# WUGEN_DSP register map
Vendor: Texas Instruments
Peripheral module from a debugger description file (folder omap5430_ES2_PUBLIC).
Registers are 32-bit, read-only, reset 0x0 unless marked. A register's access mark holds for its fields unless they carry their own. Offsets are as the file gives them; lines under a group give offsets from that group; [hi:lo] are bit positions; {n}, {i} and the like mark numbered series; 'fields as' and 'values as' point back to an identical list; <NAME> marks a mode.

## WUGEN_DSP
0x00 WUGEN_REVISION reset not defined — This register contains the IP revision code
  [31:0] REVISION — IP Revision
0x08 WUGEN_SYSCONFIG rw reset 0x1 — This register allows controlling various parameters of the WUGEN_DSP module
  [0] AUTOIDLE — Internal auto-clock gating strategy 0: Clock is free running 1: Automatic clock gating strategy is applied
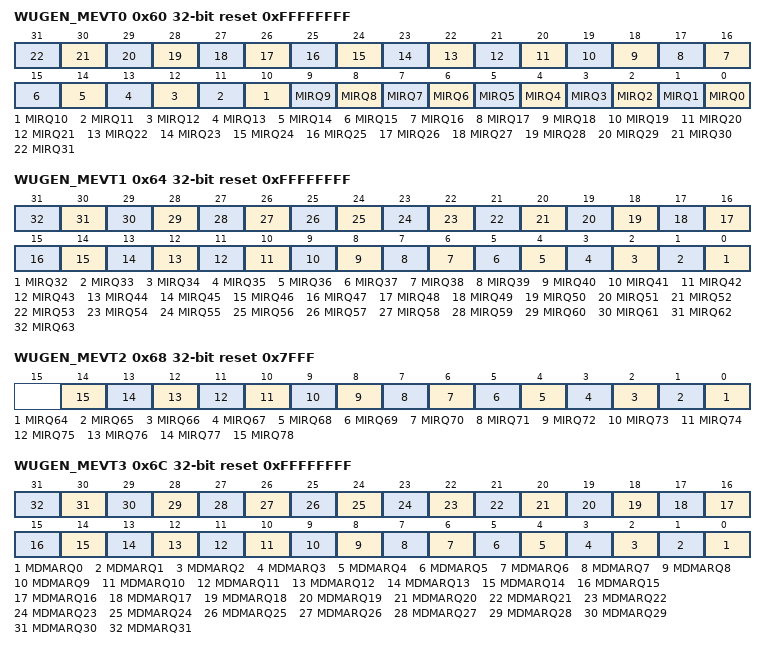
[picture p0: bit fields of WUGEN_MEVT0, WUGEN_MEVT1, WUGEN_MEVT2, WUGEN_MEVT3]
0x60 WUGEN_MEVT0 reset 0xFFFFFFFF — This register contains the interrupt mask (LSB)
  [n] MIRQ{n} (n=0..31) — Interrupt Mask bit #{n}
0x64 WUGEN_MEVT1 reset 0xFFFFFFFF — This register contains the interrupt mask (MSB)
  [n-32] MIRQ{n} (n=32..63) — Interrupt Mask bit #{n}
0x68 WUGEN_MEVT2 reset 0x7FFF — This register contains the interrupt mask (MSB)
  [n-64] MIRQ{n} (n=64..78) — Interrupt Mask bit #{n}
0x6C WUGEN_MEVT3 reset 0xFFFFFFFF — This register contains the dma request mask
  [n] MDMARQ{n} (n=0..31) — DMA request Mask bit #{n}
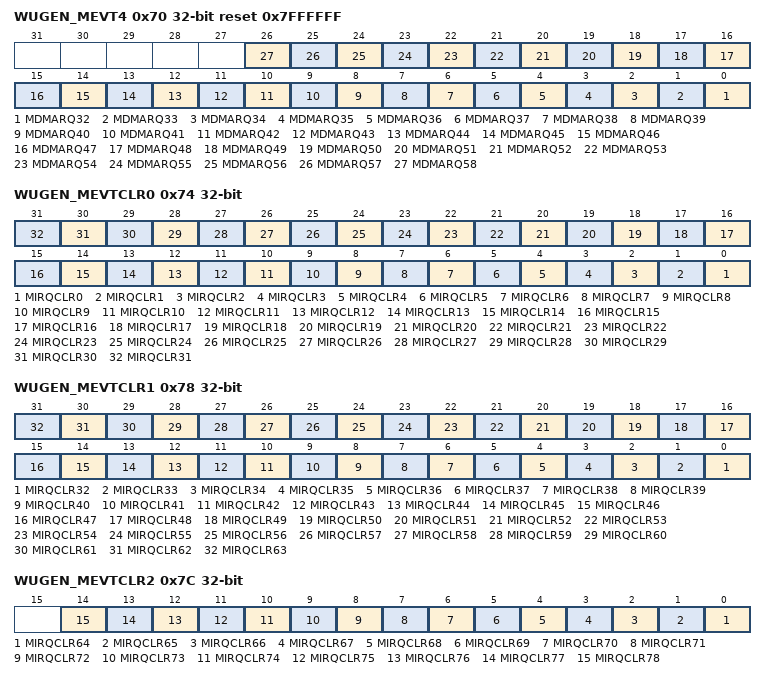
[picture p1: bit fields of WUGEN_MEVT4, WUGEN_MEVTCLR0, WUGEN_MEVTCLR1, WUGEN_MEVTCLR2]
0x70 WUGEN_MEVT4 reset 0x7FFFFFF — This register contains the dma request mask
  [n-32] MDMARQ{n} (n=32..58) — DMA request Mask bit #{n}
0x74 WUGEN_MEVTCLR0 access not given — This register is used to clear the interrupt mask bits (LSB) write 0: no effect write 1: clears the corresponding mask bit in the register reads always return 0
  [n] MIRQCLR{n} (n=0..31) — MIRQ clear #{n} (access W W1toSet)
0x78 WUGEN_MEVTCLR1 access not given — This register is used to clear the interrupt mask bits (MSB) write 0: no effect write 1: clears the corresponding mask bit in the register reads always return 0
  [n-32] MIRQCLR{n} (n=32..63) — MIRQ clear #{n} (access W W1toSet)
0x7C WUGEN_MEVTCLR2 access not given — This register is used to clear the interrupt mask bits (MSB) write 0: no effect write 1: clears the corresponding mask bit in the register reads always return 0
  [n-64] MIRQCLR{n} (n=64..78) — MIRQ clear #{n} (access W W1toSet)
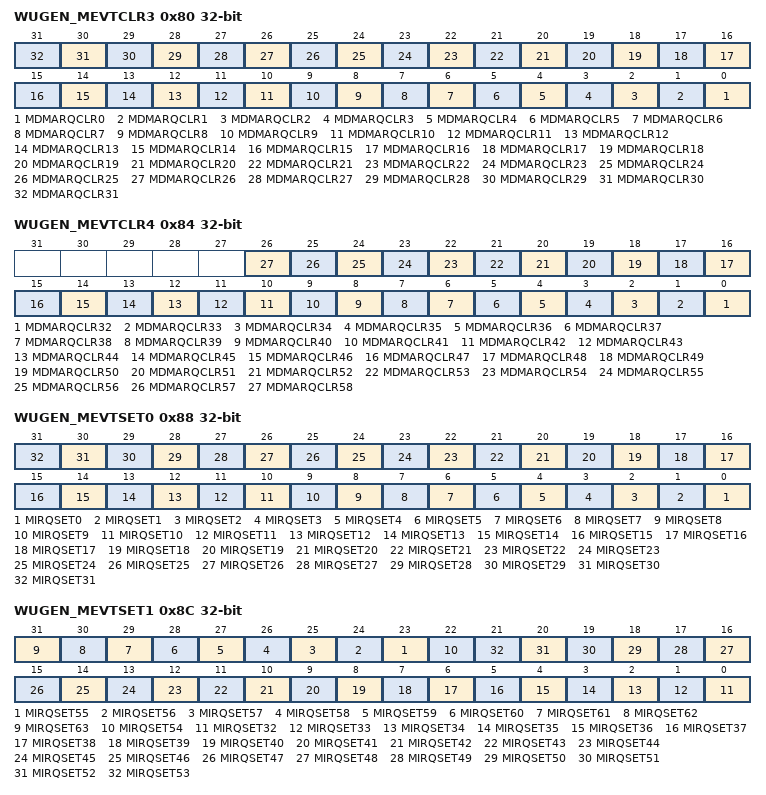
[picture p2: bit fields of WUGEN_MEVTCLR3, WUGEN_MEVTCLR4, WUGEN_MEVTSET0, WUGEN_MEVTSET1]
0x80 WUGEN_MEVTCLR3 access not given — This register is used to clear the dma request mask bits write 0: no effect write 1: clears the corresponding mask bit in the register reads always return 0
  [n] MDMARQCLR{n} (n=0..31) — MDMARQ clear #{n} (access W W1toSet)
0x84 WUGEN_MEVTCLR4 access not given — This register is used to clear the dma request mask bits write 0: no effect write 1: clears the corresponding mask bit in the register reads always return 0
  [n-32] MDMARQCLR{n} (n=32..58) — MDMARQ clear #{n} (access W W1toSet)
0x88 WUGEN_MEVTSET0 access not given — This register is used to set the interrupt mask bits (LSB) write 0: no effect write 1: sets the corresponding mask bit in the register reads always return 0
  [n] MIRQSET{n} (n=0..31) — MIRQ set #{n} (access W W1toSet)
0x8C WUGEN_MEVTSET1 access not given — This register is used to set the interrupt mask bits (MSB) write 0: no effect write 1: sets the corresponding mask bit in the register reads always return 0
  [n-32] MIRQSET{n} (n=55..63) — MIRQ set #{n} (access W W1toSet)
  [22] MIRQSET54 — MIRQ set #22 (access W W1toSet)
  [n-32] MIRQSET{n} (n=32..53) — MIRQ set #{n} (access W W1toSet)
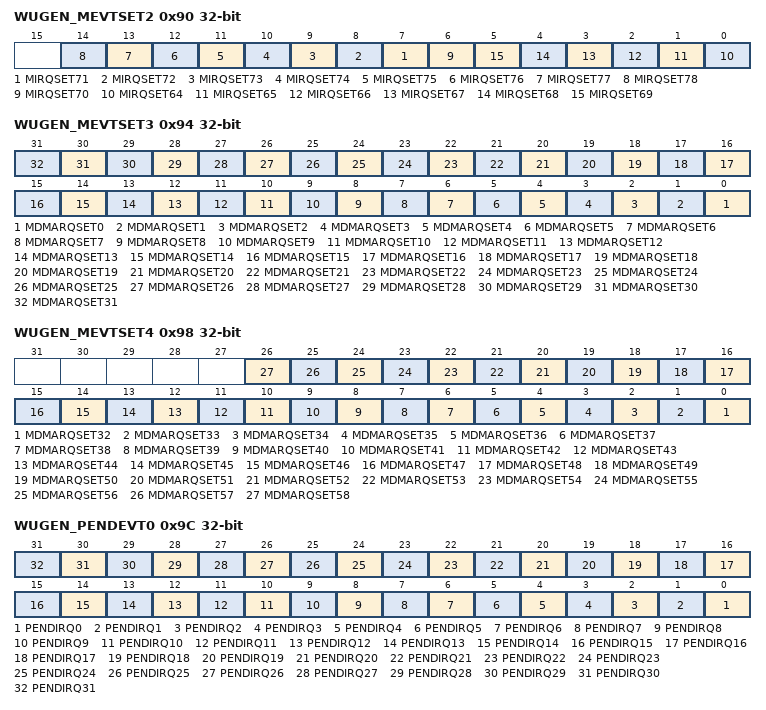
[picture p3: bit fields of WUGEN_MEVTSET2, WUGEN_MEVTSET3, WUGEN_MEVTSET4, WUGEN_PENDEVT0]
0x90 WUGEN_MEVTSET2 access not given — This register is used to set the interrupt mask bits (MSB) write 0: no effect write 1: sets the corresponding mask bit in the register reads always return 0
  [n-64] MIRQSET{n} (n=71..78) — MIRQ set #{n} (access W W1toSet)
  [6] MIRQSET70 — MIRQ set #70s (access W W1toSet)
  [n-64] MIRQSET{n} (n=64..69) — MIRQ set #{n} (access W W1toSet)
0x94 WUGEN_MEVTSET3 access not given — This register is used to set the dma requests mask bits write 0: no effect write 1: sets the corresponding mask bit in the register reads always return 0
  [n] MDMARQSET{n} (n=0..31) — MDMARQ set #{n} (access W W1toSet)
0x98 WUGEN_MEVTSET4 access not given — This register is used to set the dma requests mask bits write 0: no effect write 1: sets the corresponding mask bit in the register reads always return 0
  [n-32] MDMARQSET{n} (n=32..58) — MDMARQ set #{n} (access W W1toSet)
0x9C WUGEN_PENDEVT0 — This register holds the masked pending interrupts (LSB)
  [n] PENDIRQ{n} (n=0..31) — Masked pending interrupt number {n}
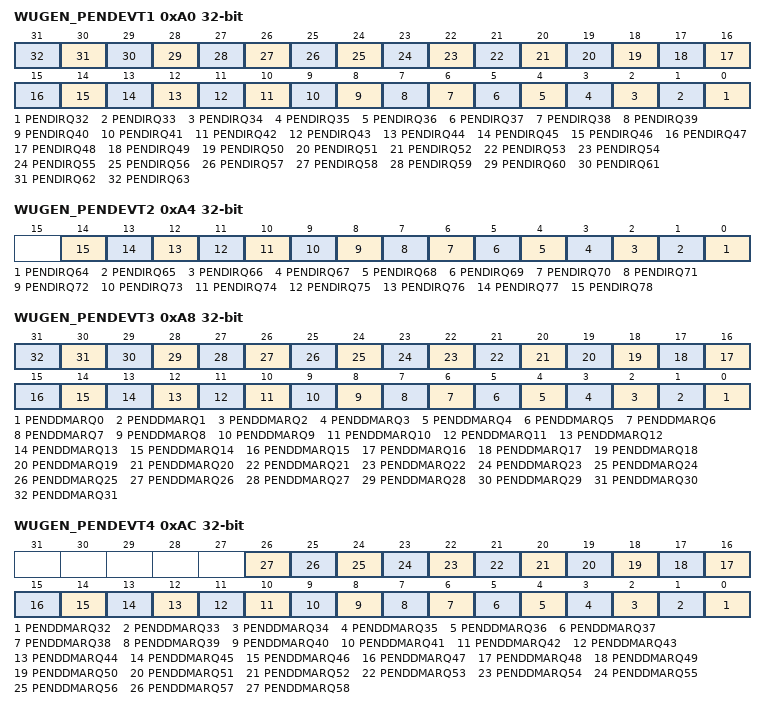
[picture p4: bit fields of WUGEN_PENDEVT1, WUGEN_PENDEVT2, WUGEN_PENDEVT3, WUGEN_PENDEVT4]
0xA0 WUGEN_PENDEVT1 — This register holds the masked pending interrupts (MSB)
  [n-32] PENDIRQ{n} (n=32..63) — Masked pending interrupt number {n}
0xA4 WUGEN_PENDEVT2 — This register holds the masked pending interrupts (MSB)
  [n-64] PENDIRQ{n} (n=64..78) — Masked pending interrupt number {n}
0xA8 WUGEN_PENDEVT3 — This register holds the masked pending dma requests
  [n] PENDDMARQ{n} (n=0..31) — Masked pending dma request number {n}
0xAC WUGEN_PENDEVT4 — This register holds the masked pending dma requests
  [n-32] PENDDMARQ{n} (n=32..58) — Masked pending dma request number {n}
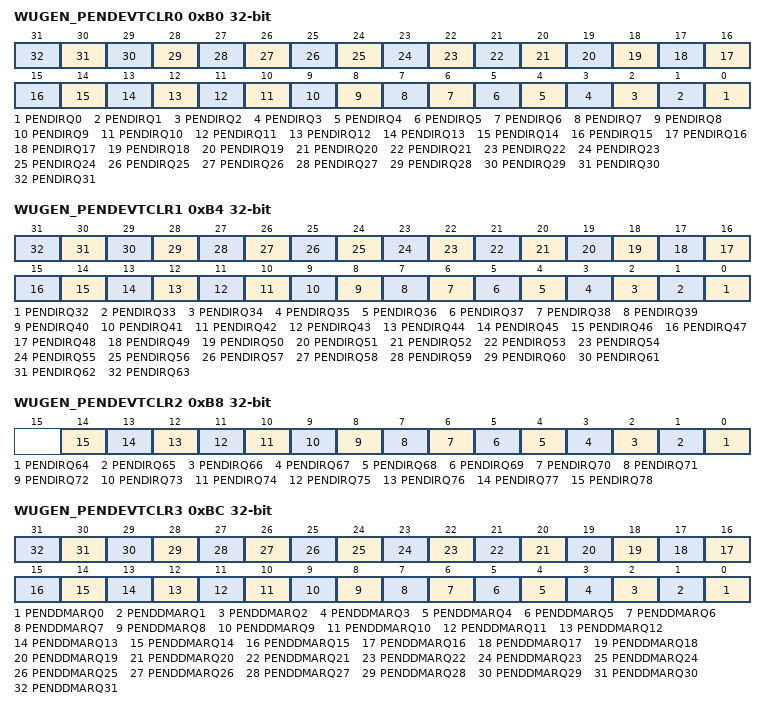
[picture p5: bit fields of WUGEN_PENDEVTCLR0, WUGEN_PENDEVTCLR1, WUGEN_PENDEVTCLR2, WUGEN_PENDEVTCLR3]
0xB0 WUGEN_PENDEVTCLR0 wo — This register clears the masked pending interrupts (LSB) : write 0: no effect write 1: clears the corresponding mask bit in the register reads always return 0
  [n] PENDIRQ{n} (n=0..31) — Masked pending interrupt number {n}
0xB4 WUGEN_PENDEVTCLR1 wo — This register clears the masked pending interrupts (MSB) : write 0: no effect write 1: clears the corresponding mask bit in the register reads always return 0
  [n-32] PENDIRQ{n} (n=32..63) — Masked pending interrupt number {n}
0xB8 WUGEN_PENDEVTCLR2 access per field — This register clears the masked pending interrupts (LSB) : write 0: no effect write 1: clears the corresponding mask bit in the register reads always return 0
  [n-64] PENDIRQ{n} wo (n=64..78) — Masked pending interrupt number {n}
0xBC WUGEN_PENDEVTCLR3 wo — This register clears the masked pending dma_requests: write 0: no effect write 1: clears the corresponding mask bit in the register reads always return 0
  [n] PENDDMARQ{n} (n=0..31) — Masked pending dma request number {n}
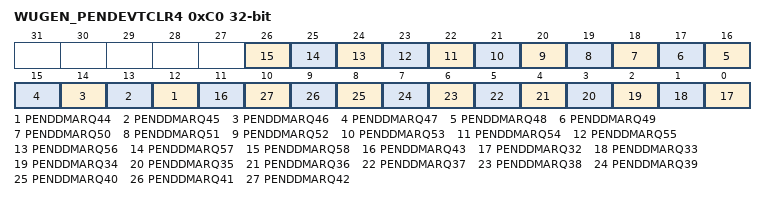
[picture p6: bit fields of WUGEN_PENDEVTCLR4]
0xC0 WUGEN_PENDEVTCLR4 access per field — This register clears the masked pending dma_requests: write 0: no effect write 1: clears the corresponding mask bit in the register reads always return 0
  [n-32] PENDDMARQ{n} wo (n=44..58) — Masked pending dma request number {n}
  [11] PENDDMARQ43 wo — Mask pending dma request number 43
  [n-32] PENDDMARQ{n} wo (n=32..42) — Masked pending dma request number {n}
